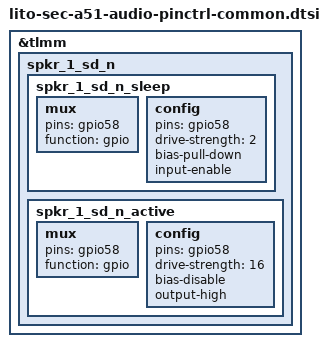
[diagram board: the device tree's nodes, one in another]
/* Copyright (c) 2019, The Linux Foundation. All rights reserved.
 *
 * This program is free software; you can redistribute it and/or modify
 * it under the terms of the GNU General Public License version 2 and
 * only version 2 as published by the Free Software Foundation.
 *
 * This program is distributed in the hope that it will be useful,
 * but WITHOUT ANY WARRANTY; without even the implied warranty of
 * MERCHANTABILITY or FITNESS FOR A PARTICULAR PURPOSE.  See the
 * GNU General Public License for more details.
 */

&tlmm {
	/* WSA speaker reset pins */
	/delete-node/ spkr_1_sd_n;
	spkr_1_sd_n {
		spkr_1_sd_n_sleep: spkr_1_sd_n_sleep {
			mux {
				pins = "gpio58";
				function = "gpio";
			};
	
			config {
				pins = "gpio58";
				drive-strength = <2>;	/* 2 mA */
				bias-pull-down;
				input-enable;
			};
		};
	
		spkr_1_sd_n_active: spkr_1_sd_n_active {
			mux {
				pins = "gpio58";
				function = "gpio";
			};
	
			config {
				pins = "gpio58";
				drive-strength = <16>;	 /* 16 mA */
				bias-disable;
				output-high;
			};
		};
	};
};
